AUTOSAR XML (schema 4-1-2)
package /ComponentTypes
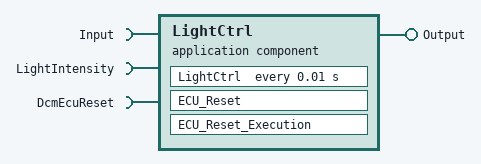
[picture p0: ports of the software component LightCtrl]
  application sw component type LightCtrl
    provide port Output: nonqueued-sender-com-spec{data-element=HeadLight, init-value=0}, provided-interface=Output
    require port Input: nonqueued-receiver-com-spec{data-element=LightSwitch, filter=data-filter-type=ALWAYS, init-value=0}, required-interface=Input
    require port LightIntensity: client-com-spec=LightIntensity, required-interface=LightIntensity
    require port DcmEcuReset: mode-switch-receiver-com-spec=DcmEcuReset, required-interface=DcmEcuReset
    behavior LightCtrl_InternalBehavior
      timing event TMT_LightCtrl: start-on-event=LightCtrl, period=0.01
      4 x swc mode switch event, all with activation=ON-ENTRY:
        MST_ECU_Reset_1: start-on-event=ECU_Reset, mode=DcmEcuReset.DcmEcuReset.HARD
        MST_ECU_Reset_2: start-on-event=ECU_Reset, mode=DcmEcuReset.DcmEcuReset.JUMPTOBOOTLOADER
        MST_ECU_Reset_3: start-on-event=ECU_Reset, mode=DcmEcuReset.DcmEcuReset.JUMPTOSYSSUPPLIERBOOTLOADER
        MST_ECU_Reset_Execution_0: start-on-event=ECU_Reset_Execution, mode=DcmEcuReset.DcmEcuReset.EXECUTE
      runnable LightCtrl
        data-receive-point-by-arguments:
          access REC_Input_AlexSpecialPort_LightSwitch: accessed-variable=Input.LightSwitch
        data-send-points:
          access SEND_Output_HeadLight: accessed-variable=Output.HeadLight
        sync call SC_LightIntensity_LightIntensity: operation=LightIntensity.LightIntensity, timeout=0
      runnable ECU_Reset: mode-access-point=DcmEcuReset.DcmEcuReset
      runnable ECU_Reset_Execution: mode-access-point=DcmEcuReset.DcmEcuReset
  swc implementation LightCtrl_Implementation: behavior=LightCtrl_InternalBehavior
    code-descriptors:
      code Default: artifact-descriptors=autosar-engineering-object={short-label=Default, category=SWSRC}
